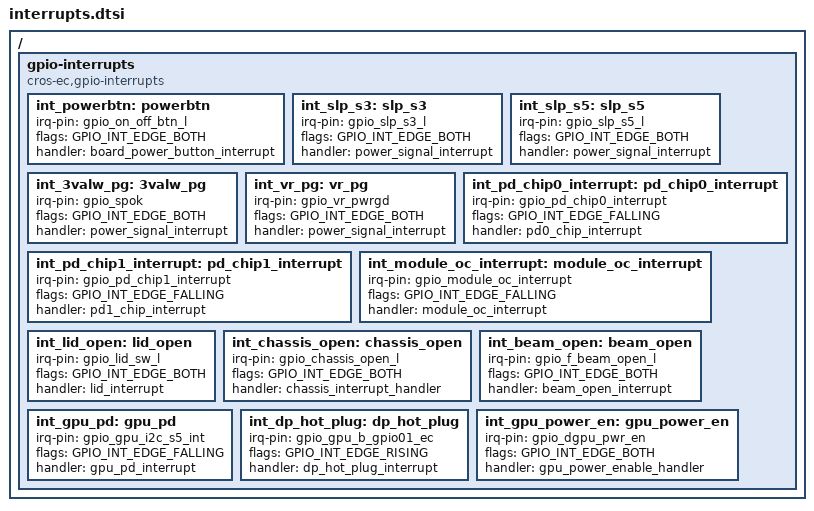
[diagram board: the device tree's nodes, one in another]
/* Copyright 2022 The ChromiumOS Authors
 * Use of this source code is governed by a BSD-style license that can be
 * found in the LICENSE file.
 */

/ {
	gpio-interrupts {
		compatible = "cros-ec,gpio-interrupts";

		int_powerbtn: powerbtn {
			irq-pin = <&gpio_on_off_btn_l>;
			flags = <GPIO_INT_EDGE_BOTH>;
			handler = "board_power_button_interrupt";
		};
		int_slp_s3: slp_s3 {
			irq-pin = <&gpio_slp_s3_l>;
			flags = <GPIO_INT_EDGE_BOTH>;
			handler = "power_signal_interrupt";
		};
		int_slp_s5: slp_s5 {
			irq-pin = <&gpio_slp_s5_l>;
			flags = <GPIO_INT_EDGE_BOTH>;
			handler = "power_signal_interrupt";
		};
		int_3valw_pg: 3valw_pg {
			irq-pin = <&gpio_spok>;
			flags = <GPIO_INT_EDGE_BOTH>;
			handler = "power_signal_interrupt";
		};
		int_vr_pg: vr_pg {
			irq-pin = <&gpio_vr_pwrgd>;
			flags = <GPIO_INT_EDGE_BOTH>;
			handler = "power_signal_interrupt";
		};
		int_pd_chip0_interrupt: pd_chip0_interrupt {
			irq-pin = <&gpio_pd_chip0_interrupt>;
			flags = <GPIO_INT_EDGE_FALLING>;
			handler = "pd0_chip_interrupt";
		};
		int_pd_chip1_interrupt: pd_chip1_interrupt {
			irq-pin = <&gpio_pd_chip1_interrupt>;
			flags = <GPIO_INT_EDGE_FALLING>;
			handler = "pd1_chip_interrupt";
		};
		int_module_oc_interrupt: module_oc_interrupt {
			irq-pin = <&gpio_module_oc_interrupt>;
			flags = <GPIO_INT_EDGE_FALLING>;
			handler = "module_oc_interrupt";
		};
		int_lid_open: lid_open {
			irq-pin = <&gpio_lid_sw_l>;
			flags = <GPIO_INT_EDGE_BOTH>;
			handler = "lid_interrupt";
		};
		int_chassis_open: chassis_open {
			irq-pin = <&gpio_chassis_open_l>;
			flags = <GPIO_INT_EDGE_BOTH>;
			handler = "chassis_interrupt_handler";
		};
		int_beam_open: beam_open {
			irq-pin = <&gpio_f_beam_open_l>;
			flags = <GPIO_INT_EDGE_BOTH>;
			handler = "beam_open_interrupt";
		};
		int_gpu_pd: gpu_pd {
			irq-pin = <&gpio_gpu_i2c_s5_int>;
			flags = <GPIO_INT_EDGE_FALLING>;
			handler = "gpu_pd_interrupt";
		};
		int_dp_hot_plug: dp_hot_plug {
			irq-pin = <&gpio_gpu_b_gpio01_ec>;
			flags = <GPIO_INT_EDGE_RISING>;
			handler = "dp_hot_plug_interrupt";
		};
		int_gpu_power_en: gpu_power_en {
			irq-pin = <&gpio_dgpu_pwr_en>;
			flags = <GPIO_INT_EDGE_BOTH>;
			handler = "gpu_power_enable_handler";
		};
	};
};
